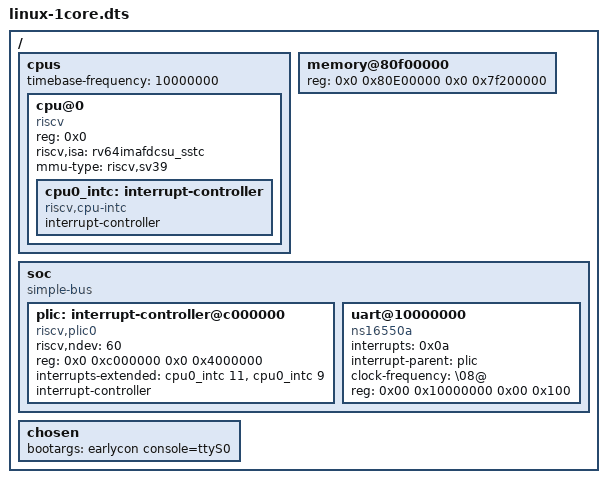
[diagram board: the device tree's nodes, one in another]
/dts-v1/;

/ {
	#address-cells = <0x2>;
	#size-cells = <0x2>;

	cpus {
		#address-cells = <0x1>;
		#size-cells = <0x0>;
		timebase-frequency = <10000000>;

		cpu@0 {
			device_type = "cpu";
			reg = <0x0>;
			status = "okay";
			compatible = "riscv";
			riscv,isa = "rv64imafdcsu_sstc";
			mmu-type = "riscv,sv39";

			cpu0_intc: interrupt-controller {
				#interrupt-cells = <0x1>;
				interrupt-controller;
				compatible = "riscv,cpu-intc";
			};
		};
	};

	memory@80f00000 {
		device_type = "memory";
		reg = <0x0 0x80E00000 0x0 0x7f200000>;
	};

	soc{
		#address-cells = <0x02>;
		#size-cells = <0x02>;
		compatible = "simple-bus";
		ranges;
		plic: interrupt-controller@c000000 {
			riscv,ndev = <60>;
			reg = <0x0 0xc000000 0x0 0x4000000>;
			interrupts-extended = <
				&cpu0_intc 11 &cpu0_intc 9 
			>;
			interrupt-controller;
			compatible = "riscv,plic0";
			#interrupt-cells = <0x1>;
		};
		uart@10000000 {
			interrupts = <0x0a>;
			interrupt-parent = <&plic>;
			clock-frequency = "\08@";
			reg = <0x00 0x10000000 0x00 0x100>;
			compatible = "ns16550a";
		};
	};
	chosen {
		bootargs = "earlycon console=ttyS0";
	};

};
